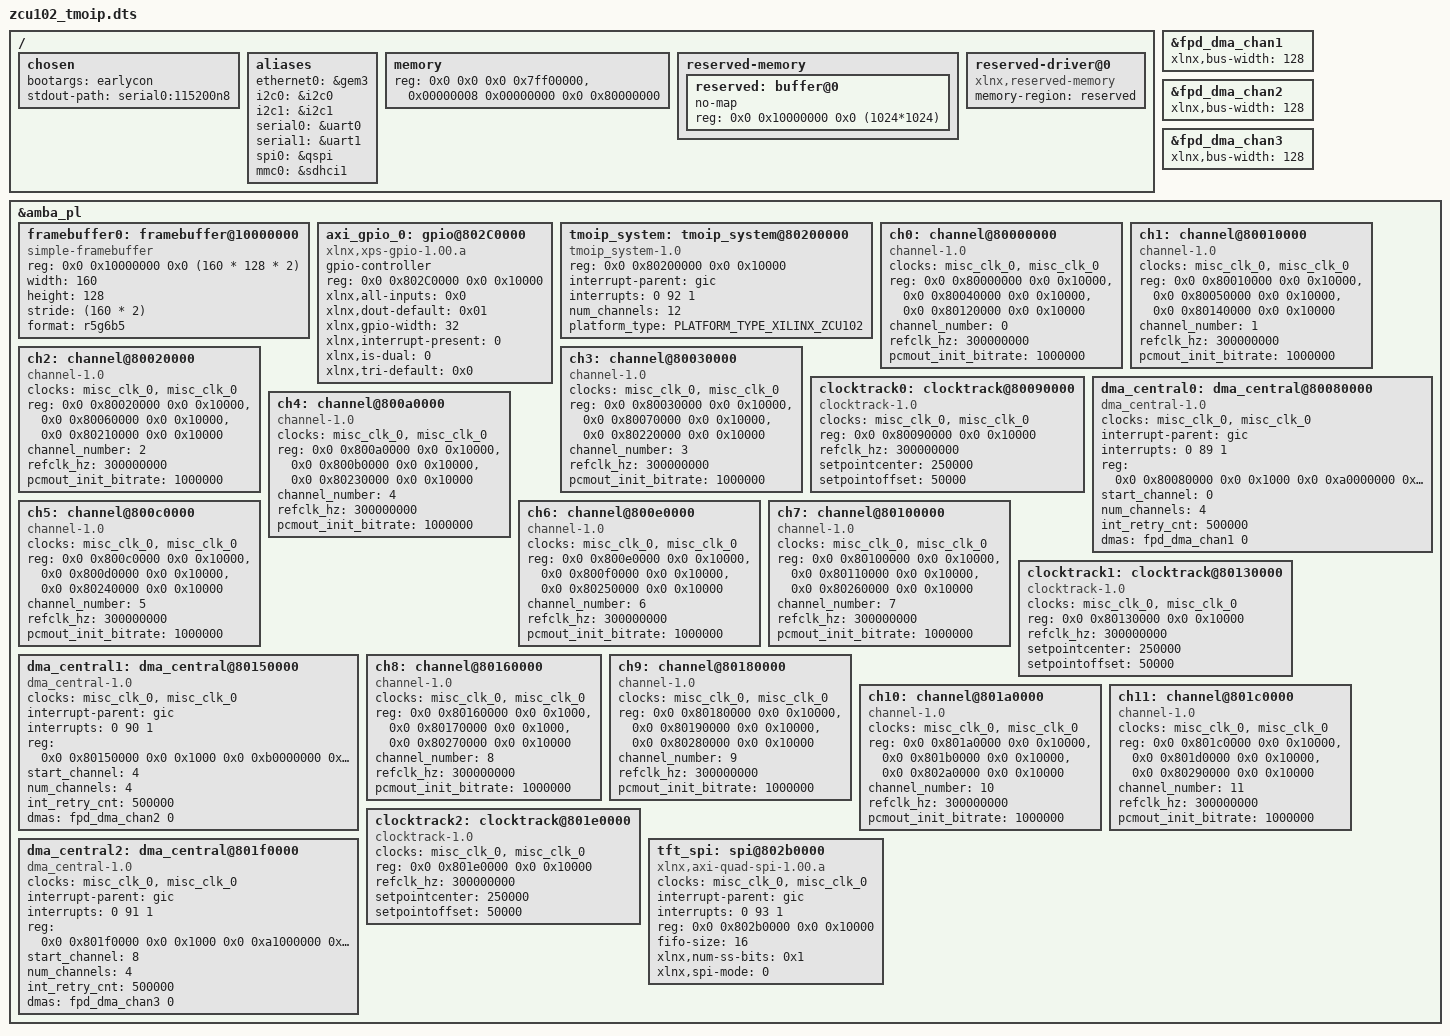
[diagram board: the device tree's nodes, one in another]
/*
 * CAUTION: This file is automatically generated by Xilinx.
 * Version: XSCT 2021.1
 * Today is: Mon Nov 15 09:07:39 2021
 */


/dts-v1/;
#include "zynqmp.dtsi"
#include "zynqmp-clk-ccf.dtsi"
#include "pl.dtsi"
#include "pcw.dtsi"

#define PLATFORM_TYPE_8_CHAN_3EG 0
#define PLATFORM_TYPE_TMOIP_3CH 1
#define PLATFORM_TYPE_TMOIP_12CH 2
#define PLATFORM_TYPE_AVNET_CC7EV 3
#define PLATFORM_TYPE_XILINX_ZCU102 4

/ {
	chosen {
		bootargs = "earlycon";
		stdout-path = "serial0:115200n8";
	};
	aliases {
		ethernet0 = &gem3;
		i2c0 = &i2c0;
		i2c1 = &i2c1;
		serial0 = &uart0;
		serial1 = &uart1;
		spi0 = &qspi;
		mmc0 = &sdhci1;
	};
	memory {
		device_type = "memory";
		reg = <0x0 0x0 0x0 0x7ff00000>, <0x00000008 0x00000000 0x0 0x80000000>;
	};

   	reserved-memory {
        #address-cells = <2>;
        #size-cells = <2>;
		ranges;
  
		reserved: buffer@0 {
           no-map;
		   reg = <0x0 0x10000000 0x0 (1024*1024)>;
      	};
   	};
  	reserved-driver@0 {
      	compatible = "xlnx,reserved-memory";
		memory-region = <&reserved>;
   	};	

};

&fpd_dma_chan1 {
	status = "okay";
	#dma-cells = <1>;
	xlnx,bus-width = <128>;
};

&fpd_dma_chan2 {
	status = "okay";
	#dma-cells = <1>;
	xlnx,bus-width = <128>;
};

&fpd_dma_chan3 {
	status = "okay";
	#dma-cells = <1>;
	xlnx,bus-width = <128>;
};
    
&amba_pl {
    framebuffer0: framebuffer@10000000 {
	     compatible = "simple-framebuffer";
         #address-cells = <2>;
         #size-cells = <2>;
	     reg = <0x0 0x10000000 0x0 (160 * 128 * 2)>;
	     width = <160>;
	     height = <128>;
	     stride = < (160 * 2) >;
         //format = "a8r8g8b8";
	     format = "r5g6b5";
	};
    axi_gpio_0: gpio@802C0000 {
	      #gpio-cells = <2>;
		  compatible = "xlnx,xps-gpio-1.00.a";
		  gpio-controller ;
	      reg = <0x0 0x802C0000 0x0 0x10000 >;
          xlnx,all-inputs = <0x0>;
          xlnx,dout-default = <0x01>;
          xlnx,gpio-width = <32>;
          xlnx,interrupt-present = <0>;
          xlnx,is-dual = <0>;
		  xlnx,tri-default = <0x0>;
	} ;			
	tmoip_system: tmoip_system@80200000 {
	   compatible = "tmoip_system-1.0";
   	   reg = <0x0 0x80200000 0x0 0x10000>;
       interrupt-parent = <&gic>;
       interrupts = <0 92 1>;
       num_channels = <12>;
       platform_type = <PLATFORM_TYPE_XILINX_ZCU102>;
    };
	ch0: channel@80000000 {
	      compatible = "channel-1.0";
	      clock-names = "axi_lite_aclk";
	      clocks = <&misc_clk_0>, <&misc_clk_0>;
	      reg = <0x0 0x80000000 0x0 0x10000>,
                <0x0 0x80040000 0x0 0x10000>,
                <0x0 0x80120000 0x0 0x10000>;
          reg-names = "channel_in", "channel_out", "line_test";                                        
 		  channel_number = <0>;
		  refclk_hz = <300000000>;
          pcmout_init_bitrate = <1000000>;
    };
	ch1: channel@80010000 {
	      compatible = "channel-1.0";
	      clock-names = "axi_lite_aclk";
	      clocks = <&misc_clk_0>, <&misc_clk_0>;
	      reg = <0x0 0x80010000 0x0 0x10000>,
                <0x0 0x80050000 0x0 0x10000>,
                <0x0 0x80140000 0x0 0x10000>;
          reg-names = "channel_in", "channel_out", "line_test";                                        
 		  channel_number = <1>;
		  refclk_hz = <300000000>;
          pcmout_init_bitrate = <1000000>;
    };
	ch2: channel@80020000 {
	      compatible = "channel-1.0";
	      clock-names = "axi_lite_aclk";
	      clocks = <&misc_clk_0>, <&misc_clk_0>;
	      reg = <0x0 0x80020000 0x0 0x10000>,
                <0x0 0x80060000 0x0 0x10000>,
                <0x0 0x80210000 0x0 0x10000>;
          reg-names = "channel_in", "channel_out", "line_test";                                        
 		  channel_number = <2>;
		  refclk_hz = <300000000>;
          pcmout_init_bitrate = <1000000>;
    };
	ch3: channel@80030000 {
	      compatible = "channel-1.0";
	      clock-names = "axi_lite_aclk";
	      clocks = <&misc_clk_0>, <&misc_clk_0>;
	      reg = <0x0 0x80030000 0x0 0x10000>,
                <0x0 0x80070000 0x0 0x10000>,
                <0x0 0x80220000 0x0 0x10000>;
          reg-names = "channel_in", "channel_out", "line_test";                                        
 		  channel_number = <3>;
		  refclk_hz = <300000000>;
          pcmout_init_bitrate = <1000000>;
    };
	clocktrack0: clocktrack@80090000 {
	      compatible = "clocktrack-1.0";
	      clock-names = "axi_lite_aclk";
	      clocks = <&misc_clk_0>, <&misc_clk_0>;
     	  reg = <0x0 0x80090000 0x0 0x10000>;
		  refclk_hz = <300000000>;
	      setpointcenter = <250000>;
	      setpointoffset = <50000>;
    };
    dma_central0: dma_central@80080000 {
          compatible = "dma_central-1.0";
	      clock-names = "axi_lite_aclk", "axis_in_aclk";
          clocks = <&misc_clk_0>, <&misc_clk_0>;
          interrupt-parent = <&gic>;
          interrupts = <0 89 1>;
          reg = <0x0 0x80080000 0x0 0x1000 0x0 0xa0000000 0x0 0x100000>;
          start_channel = <0>;
          num_channels = <4>;
          int_retry_cnt = <500000>;
          dmas = <&fpd_dma_chan1 0>;
          dma-names = "dma";
	};
	ch4: channel@800a0000 {
	      compatible = "channel-1.0";
	      clock-names = "axi_lite_aclk";
	      clocks = <&misc_clk_0>, <&misc_clk_0>;
	      reg = <0x0 0x800a0000 0x0 0x10000>,
                <0x0 0x800b0000 0x0 0x10000>,
                <0x0 0x80230000 0x0 0x10000>;
          reg-names = "channel_in", "channel_out", "line_test";                                        
 		  channel_number = <4>;
		  refclk_hz = <300000000>;
          pcmout_init_bitrate = <1000000>;
    };
	ch5: channel@800c0000 {
	      compatible = "channel-1.0";
	      clock-names = "axi_lite_aclk";
	      clocks = <&misc_clk_0>, <&misc_clk_0>;
	      reg = <0x0 0x800c0000 0x0 0x10000>,
                <0x0 0x800d0000 0x0 0x10000>,
                <0x0 0x80240000 0x0 0x10000>;
          reg-names = "channel_in", "channel_out", "line_test";                                        
 		  channel_number = <5>;
		  refclk_hz = <300000000>;
          pcmout_init_bitrate = <1000000>;
    };
	ch6: channel@800e0000 {
	      compatible = "channel-1.0";
	      clock-names = "axi_lite_aclk";
	      clocks = <&misc_clk_0>, <&misc_clk_0>;
	      reg = <0x0 0x800e0000 0x0 0x10000>,
                <0x0 0x800f0000 0x0 0x10000>,
                <0x0 0x80250000 0x0 0x10000>;
          reg-names = "channel_in", "channel_out", "line_test";                                        
 		  channel_number = <6>;
		  refclk_hz = <300000000>;
          pcmout_init_bitrate = <1000000>;
    };
	ch7: channel@80100000 {
	      compatible = "channel-1.0";
	      clock-names = "axi_lite_aclk";
	      clocks = <&misc_clk_0>, <&misc_clk_0>;
	      reg = <0x0 0x80100000 0x0 0x10000>,
                <0x0 0x80110000 0x0 0x10000>,
                <0x0 0x80260000 0x0 0x10000>;
          reg-names = "channel_in", "channel_out", "line_test";                                        
 		  channel_number = <7>;
		  refclk_hz = <300000000>;
          pcmout_init_bitrate = <1000000>;
    };
	clocktrack1: clocktrack@80130000 {
	      compatible = "clocktrack-1.0";
	      clock-names = "axi_lite_aclk";
	      clocks = <&misc_clk_0>, <&misc_clk_0>;
     	  reg = <0x0 0x80130000 0x0 0x10000>;
		  refclk_hz = <300000000>;
	      setpointcenter = <250000>;
	      setpointoffset = <50000>;
    };
    dma_central1: dma_central@80150000 {
          compatible = "dma_central-1.0";
	      clock-names = "axi_lite_aclk", "axis_in_aclk";
          clocks = <&misc_clk_0>, <&misc_clk_0>;
          interrupt-parent = <&gic>;
          interrupts = <0 90 1>;
          reg = <0x0 0x80150000 0x0 0x1000 0x0 0xb0000000 0x0 0x100000>;
          start_channel = <4>;
          num_channels = <4>;
          int_retry_cnt = <500000>;
          dmas = <&fpd_dma_chan2 0>;
          dma-names = "dma";
	};
	ch8: channel@80160000 {
	      compatible = "channel-1.0";
	      clock-names = "axi_lite_aclk";
	      clocks = <&misc_clk_0>, <&misc_clk_0>;
	      reg = <0x0 0x80160000 0x0 0x1000>,
                <0x0 0x80170000 0x0 0x1000>,
                <0x0 0x80270000 0x0 0x10000>;
          reg-names = "channel_in", "channel_out", "line_test";                                        
 		  channel_number = <8>;
		  refclk_hz = <300000000>;
          pcmout_init_bitrate = <1000000>;

    };
	ch9: channel@80180000 {
	      compatible = "channel-1.0";
	      clock-names = "axi_lite_aclk";
	      clocks = <&misc_clk_0>, <&misc_clk_0>;
	      reg = <0x0 0x80180000 0x0 0x10000>,
                <0x0 0x80190000 0x0 0x10000>,
                <0x0 0x80280000 0x0 0x10000>;
          reg-names = "channel_in", "channel_out", "line_test";                                        
 		  channel_number = <9>;
		  refclk_hz = <300000000>;
          pcmout_init_bitrate = <1000000>;
    };
	ch10: channel@801a0000 {
	      compatible = "channel-1.0";
	      clock-names = "axi_lite_aclk";
	      clocks = <&misc_clk_0>, <&misc_clk_0>;
	      reg = <0x0 0x801a0000 0x0 0x10000>,
                <0x0 0x801b0000 0x0 0x10000>,
                <0x0 0x802a0000 0x0 0x10000>;
          reg-names = "channel_in", "channel_out", "line_test";                                        
 		  channel_number = <10>;
		  refclk_hz = <300000000>;
          pcmout_init_bitrate = <1000000>;
    };
	ch11: channel@801c0000 {
	      compatible = "channel-1.0";
	      clock-names = "axi_lite_aclk";
	      clocks = <&misc_clk_0>, <&misc_clk_0>;
	      reg = <0x0 0x801c0000 0x0 0x10000>,
                <0x0 0x801d0000 0x0 0x10000>,
                <0x0 0x80290000 0x0 0x10000>;
          reg-names = "channel_in", "channel_out", "line_test";                                        
 		  channel_number = <11>;
		  refclk_hz = <300000000>;
          pcmout_init_bitrate = <1000000>;
    };
	clocktrack2: clocktrack@801e0000 {
	      compatible = "clocktrack-1.0";
	      clock-names = "axi_lite_aclk";
	      clocks = <&misc_clk_0>, <&misc_clk_0>;
     	  reg = <0x0 0x801e0000 0x0 0x10000>;
		  refclk_hz = <300000000>;
	      setpointcenter = <250000>;
	      setpointoffset = <50000>;
    };
    dma_central2: dma_central@801f0000 {
          compatible = "dma_central-1.0";
	      clock-names = "axi_lite_aclk", "axis_in_aclk";
          clocks = <&misc_clk_0>, <&misc_clk_0>;
          interrupt-parent = <&gic>;
          interrupts = <0 91 1>;
          reg = <0x0 0x801f0000 0x0 0x1000 0x0 0xa1000000 0x0 0x100000>;
          start_channel = <8>;
          num_channels = <4>;
          int_retry_cnt = <500000>;
          dmas = <&fpd_dma_chan3 0>;
          dma-names = "dma";
	};
    tft_spi: spi@802b0000 {
			#address-cells = <1>;
			#size-cells = <0>;
			compatible = "xlnx,axi-quad-spi-1.00.a", "xlnx,xps-spi-2.00.a";
			clock-names = "ext_spi_clk", "s_axi_aclk";
			clocks = <&misc_clk_0>, <&misc_clk_0>;
			interrupt-parent = <&gic>;
			interrupts = <0 93 1>;
			reg = <0x0 0x802b0000 0x0 0x10000>;
			fifo-size = <16>;
			xlnx,num-ss-bits = <0x1>;
			xlnx,spi-mode = <0>;
			//			spidev: spidev@0 {
			//     compatible = "rohm,dh2228fv";
			//     spi-max-frequency = <50000000>;
			//     reg = <0>;
			//};
/*    
			lcd0: lcd0@0 {
			     compatible = "ilitek,ili9163";
			     reg = <0>;
			     spi_max_frequency = <9375000>;
			     rotate = <90>;
			     swapxy = <1>;
			     width = <128>;
			     height = <160>;
			     rgb;
			     fps = <5>;
			     buswidth = <8>;
			     reset-gpios = <&axi_gpio_0 0 1>;
			     dc-gpios = <&axi_gpio_0 1 0>;
			};
*/    
	};
};
